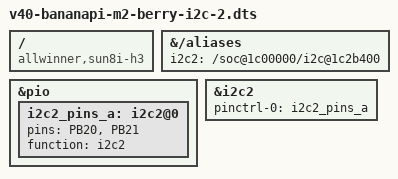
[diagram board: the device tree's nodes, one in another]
/dts-v1/;
/plugin/;

/ {
	compatible = "allwinner,sun8i-h3";

	fragment@0 {
		target-path = "/aliases";
		__overlay__ {
			i2c2 = "/soc@1c00000/i2c@1c2b400";
		};
	};

	fragment@1 {
		target = <&pio>;
		__overlay__ {
			i2c2_pins_a: i2c2@0 {
				pins = "PB20", "PB21";
				function = "i2c2";
			};
		};
	};

	fragment@2 {
		target = <&i2c2>;
		__overlay__ {
			pinctrl-names = "default";
			pinctrl-0 = <&i2c2_pins_a>;
			status = "okay";
		};
	};
};
